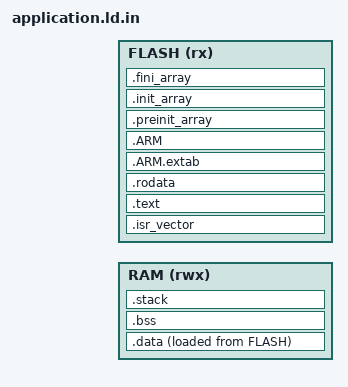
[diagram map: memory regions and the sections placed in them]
ENTRY(ResetHandler)

_STACK_SIZE = 0x400;

MEMORY
{
	RAM    (rwx): ORIGIN = @APP_RAM_START@,    LENGTH = @APP_RAM_SIZE@
	FLASH  (rx):  ORIGIN = @APP_CODE_START@,   LENGTH = @APP_CODE_SIZE@
}

SECTIONS
{
	.isr_vector :
	{
		. = ALIGN(4);
		KEEP(*(.isr_vector))
		. = ALIGN(4);
	} > FLASH

	.text :
	{
		. = ALIGN(4);
		*(.text)
		*(.text*)
		*(.glue_7)
		*(.glue_7t)
		*(.eh_frame)
		KEEP (*(.init))
		KEEP (*(.fini))
		. = ALIGN(4);
		_etext = .;
	} > FLASH

	.rodata :
	{
		. = ALIGN(4);
		*(.rodata)
		*(.rodata*)
		. = ALIGN(4);
	} > FLASH

	.ARM.extab :
	{
		. = ALIGN(4);
		*(.ARM.extab* .gnu.linkonce.armextab.*)
		. = ALIGN(4);
	} > FLASH

	.ARM :
	{
		. = ALIGN(4);
		__exidx_start = .;
		*(.ARM.exidx*)
		__exidx_end = .;
		. = ALIGN(4);
	} > FLASH

	.preinit_array :
	{
		. = ALIGN(4);
		PROVIDE_HIDDEN (__preinit_array_start = .);
		KEEP (*(.preinit_array*))
		PROVIDE_HIDDEN (__preinit_array_end = .);
		. = ALIGN(4);
	} > FLASH

	.init_array :
	{
		. = ALIGN(4);
		PROVIDE_HIDDEN (__init_array_start = .);
		KEEP (*(SORT(.init_array.*)))
		KEEP (*(.init_array*))
		PROVIDE_HIDDEN (__init_array_end = .);
		. = ALIGN(4);
	} > FLASH

	.fini_array :
	{
		. = ALIGN(4);
		PROVIDE_HIDDEN (__fini_array_start = .);
		KEEP (*(SORT(.fini_array.*)))
		KEEP (*(.fini_array*))
		PROVIDE_HIDDEN (__fini_array_end = .);
		. = ALIGN(4);
	} > FLASH

	_sidata = LOADADDR(.data);

	.data :
	{
		. = ALIGN(4);
		_sdata = .;
		*(.data)	
		*(.data*) 
		*(.RamFunc)
		*(.RamFunc*)
		. = ALIGN(4);
		_edata = .;
	} > RAM AT > FLASH

	.bss :
	{
		. = ALIGN(4);
		_sbss = .;
		*(.bss)
		*(.bss*)
		*(COMMON)
		. = ALIGN(4);
		_ebss = .;
	} > RAM

	.stack :
	{
		. = ALIGN(8);
		PROVIDE ( end = . );
		PROVIDE ( _end = . );
		. = . + _STACK_SIZE;
		. = ALIGN(8);
		_estack = .;
	} > RAM

	/DISCARD/ :
	{
		libc.a ( * )
		libm.a ( * )
		libgcc.a ( * )
	}

	.ARM.attributes 0 :
	{
		*(.ARM.attributes)
	}
}
